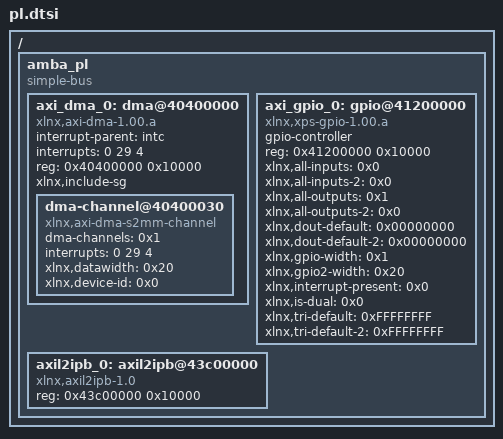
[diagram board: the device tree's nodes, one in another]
/*
 * CAUTION: This file is automatically generated by Xilinx.
 * Version:  
 * Today is: Thu Aug 11 22:00:13 2016
*/


/ {
	amba_pl: amba_pl {
		#address-cells = <1>;
		#size-cells = <1>;
		compatible = "simple-bus";
		ranges ;
		axi_dma_0: dma@40400000 {
			#dma-cells = <1>;
			compatible = "xlnx,axi-dma-1.00.a";
			interrupt-parent = <&intc>;
			interrupts = <0 29 4>;
			reg = <0x40400000 0x10000>;
			xlnx,include-sg ;
			dma-channel@40400030 {
				compatible = "xlnx,axi-dma-s2mm-channel";
				dma-channels = <0x1>;
				interrupts = <0 29 4>;
				xlnx,datawidth = <0x20>;
				xlnx,device-id = <0x0>;
			};
		};
		axi_gpio_0: gpio@41200000 {
			#gpio-cells = <2>;
			compatible = "xlnx,xps-gpio-1.00.a";
			gpio-controller ;
			reg = <0x41200000 0x10000>;
			xlnx,all-inputs = <0x0>;
			xlnx,all-inputs-2 = <0x0>;
			xlnx,all-outputs = <0x1>;
			xlnx,all-outputs-2 = <0x0>;
			xlnx,dout-default = <0x00000000>;
			xlnx,dout-default-2 = <0x00000000>;
			xlnx,gpio-width = <0x1>;
			xlnx,gpio2-width = <0x20>;
			xlnx,interrupt-present = <0x0>;
			xlnx,is-dual = <0x0>;
			xlnx,tri-default = <0xFFFFFFFF>;
			xlnx,tri-default-2 = <0xFFFFFFFF>;
		};
		axil2ipb_0: axil2ipb@43c00000 {
			compatible = "xlnx,axil2ipb-1.0";
			reg = <0x43c00000 0x10000>;
		};
	};
};
